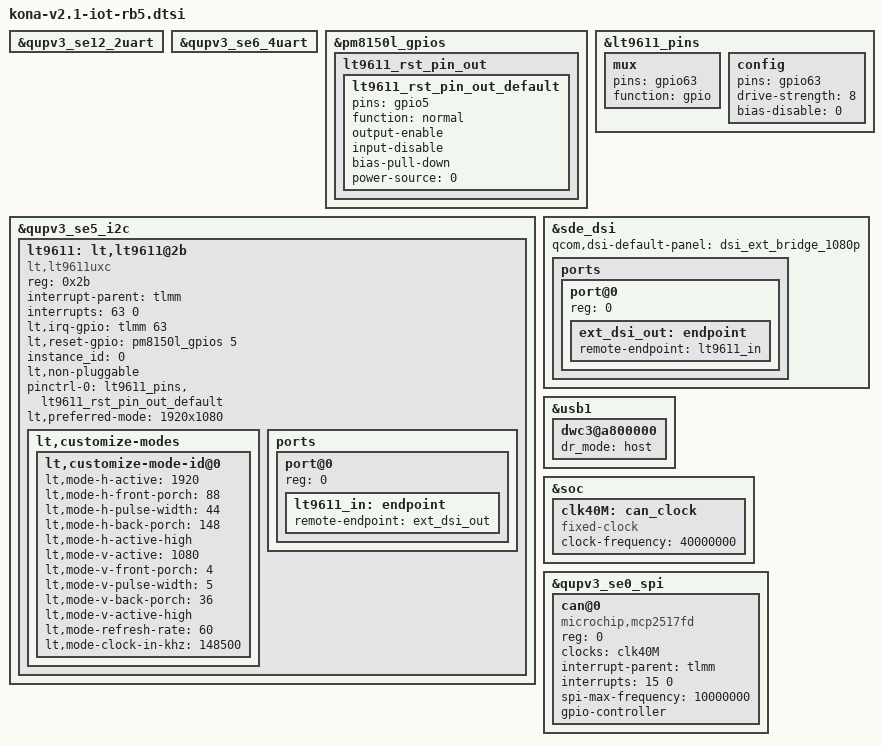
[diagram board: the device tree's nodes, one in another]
#include "kona-qrd.dtsi"
#include "kona-iot-rb5-audio.dtsi"

&qupv3_se12_2uart {
	status = "okay";
};

&qupv3_se6_4uart {
	status = "ok";
};

&pm8150l_gpios {
	lt9611_rst_pin_out {
		lt9611_rst_pin_out_default: lt9611_rst_pin_out_default {
		pins = "gpio5";
		function = "normal";
		output-enable;
		input-disable;
		bias-pull-down;
		power-source = <0>;
		};
	};
};

&lt9611_pins {
	mux {
		pins = "gpio63";
		function = "gpio";
	};

	config {
		pins = "gpio63";
		drive-strength = <8>;
		bias-disable = <0>;
	};
};

&qupv3_se5_i2c {
	status = "ok";
	lt9611: lt,lt9611@2b {
		compatible = "lt,lt9611uxc";
		reg = <0x2b>;
		interrupt-parent = <&tlmm>;
		interrupts = <63 0>;
		interrupt-names = "lt_irq";
		lt,irq-gpio = <&tlmm 63 0x0>;
		lt,reset-gpio = <&pm8150l_gpios 5 0x0>;
		instance_id = <0>;
		lt,non-pluggable;

		pinctrl-names = "default";
		pinctrl-0 = <&lt9611_pins &lt9611_rst_pin_out_default>;

		lt,preferred-mode = "1920x1080";

		lt,customize-modes {
			lt,customize-mode-id@0 {
				lt,mode-h-active = <1920>;
				lt,mode-h-front-porch = <88>;
				lt,mode-h-pulse-width = <44>;
				lt,mode-h-back-porch = <148>;
				lt,mode-h-active-high;
				lt,mode-v-active = <1080>;
				lt,mode-v-front-porch = <4>;
				lt,mode-v-pulse-width = <5>;
				lt,mode-v-back-porch = <36>;
				lt,mode-v-active-high;
				lt,mode-refresh-rate = <60>;
				lt,mode-clock-in-khz = <148500>;
			};
		};

		ports {
			#address-cells = <1>;
			#size-cells = <0>;

			port@0 {
				reg = <0>;
				lt9611_in: endpoint {
					remote-endpoint = <&ext_dsi_out>;
				};
			};

		};
	};
};

&sde_dsi {
	qcom,dsi-default-panel = <&dsi_ext_bridge_1080p>;

	ports {
		#address-cells = <1>;
		#size-cells = <0>;

		port@0 {
			reg = <0>;
			ext_dsi_out: endpoint {
				remote-endpoint = <&lt9611_in>;
			};
		};
	};
};

&usb1 {
	/delete-property/ qcom,default-mode-none;
	dwc3@a800000 {
		dr_mode = "host";
	};
};

&soc {
	clk40M: can_clock {
		compatible = "fixed-clock";
		#clock-cells = <0>;
		clock-frequency = <40000000>;
	};
};

&qupv3_se0_spi {
	status = "okay";
	can@0 {
		compatible = "microchip,mcp2517fd";
		reg = <0>;
		clocks = <&clk40M>;
		interrupt-parent = <&tlmm>;
		interrupts = <15 0>;
		interrupt-names = "can_irq";
		spi-max-frequency = <10000000>;
		gpio-controller;
		status = "okay";
	};
};
